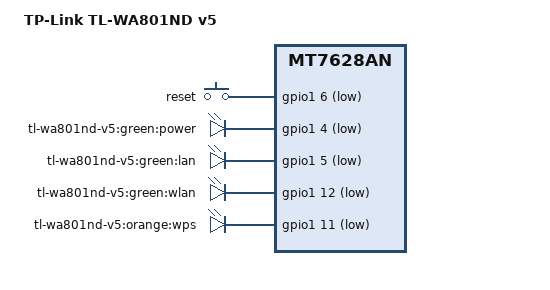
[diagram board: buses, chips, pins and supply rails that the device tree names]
/dts-v1/;

#include "TPLINK-8M.dtsi"

#include <dt-bindings/gpio/gpio.h>
#include <dt-bindings/input/input.h>

/ {
	compatible = "tplink,tl-wa801nd-v5", "mediatek,mt7628an-soc";
	model = "TP-Link TL-WA801ND v5";

	aliases {
		led-boot = &led_power;
		led-failsafe = &led_power;
		led-running = &led_power;
		led-upgrade = &led_power;
	};

	gpio-keys-polled {
		compatible = "gpio-keys-polled";
		poll-interval = <20>;

		reset {
			label = "reset";
			gpios = <&gpio1 6 GPIO_ACTIVE_LOW>;
			linux,code = <KEY_RESTART>;
		};
	};

	gpio-leds {
		compatible = "gpio-leds";

		led_power: power {
			label = "tl-wa801nd-v5:green:power";
			gpios = <&gpio1 4 GPIO_ACTIVE_LOW>;
		};

		lan {
			label = "tl-wa801nd-v5:green:lan";
			gpios = <&gpio1 5 GPIO_ACTIVE_LOW>;
		};

		wlan {
			label = "tl-wa801nd-v5:green:wlan";
			gpios = <&gpio1 12 GPIO_ACTIVE_LOW>;
		};

		wps {
			label = "tl-wa801nd-v5:orange:wps";
			gpios = <&gpio1 11 GPIO_ACTIVE_LOW>;
		};
	};
};

&pinctrl {
	state_default: pinctrl0 {
		gpio {
			ralink,group = "p0led_an", "perst", "refclk", "wdt", "wled_an";
			ralink,function = "gpio";
		};
	};
};
